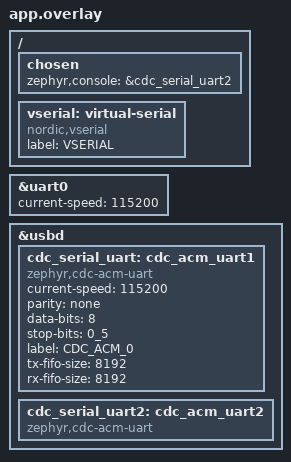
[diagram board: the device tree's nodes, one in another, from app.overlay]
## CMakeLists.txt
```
#
# Copyright (c) 2022 Nordic Semiconductor ASA
#
# SPDX-License-Identifier: LicenseRef-Nordic-5-Clause
#

cmake_minimum_required(VERSION 3.20.5)
cmake_policy(SET CMP0057 NEW)

find_package(Zephyr REQUIRED HINTS $ENV{ZEPHYR_BASE})

add_compile_options(-Wno-unused-function -Wno-unused-variable)


list(APPEND CMAKE_MODULE_PATH ${ZEPHYR_BASE}/modules/nanopb)
include(nanopb)

project(embedded80211_serial)

target_include_directories(app PUBLIC ${ZEPHYR_BASE}/subsys/net/ip)

set(PROTO_DIR ${CMAKE_CURRENT_SOURCE_DIR}/../protos)
set(PROTO_FILES ${PROTO_DIR}/wifi.proto ${PROTO_DIR}/network_interface.proto)

# Generate C sources from .proto files
# The function will create targets for generating the .pb.c and .pb.h files.
zephyr_nanopb_sources(app ${PROTO_FILES})

# we need to be able to include generated protobuf header files
zephyr_library_include_directories(${CMAKE_CURRENT_BINARY_DIR})

target_include_directories(app PUBLIC src)

#src/wifi_data.c


target_sources(app PRIVATE
	src/main.c
	src/multiplexer.c
)

if(CONFIG_SERIAL_PROXY_WIFI_MGMT)
	target_sources(app PRIVATE src/wifi_mgmt_proxy.c)
endif()

if(CONFIG_SERIAL_PROXY_WIFI_DATA)
	target_sources(app PRIVATE src/wifi_data.c)
endif()

if(CONFIG_SERIAL_PROXY_NET_IF_MGMT)
	target_sources(app PRIVATE src/net_if_mgmt_proxy.c)
endif()

if(CONFIG_SERIAL_PROXY_BT)
	target_sources(app PRIVATE src/bt_proxy.c)
endif()

if(CONFIG_SERIAL_PROXY_OT)
	target_sources(app PRIVATE src/ot_proxy.c)
endif()

if(CONFIG_SERIAL_PROXY_VSERIAL)
	target_sources(app PRIVATE src/vserial.c)
endif()

add_subdirectory(src/serial)
```

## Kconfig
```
#
# Copyright (c) 2022 Nordic Semiconductor
#
# SPDX-License-Identifier: LicenseRef-Nordic-5-Clause
#

source "Kconfig.zephyr"

menu "Nordic Sta sample"

config CONNECTION_IDLE_TIMEOUT
	int "Time to be waited for a station to connect"
	default 30

config NRF70_QSPI_ENCRYPTION_KEY
	string "16 bytes QSPI encryption key, only for testing purposes"
	depends on BOARD_NRF7002DK_NRF5340_CPUAPP
	help
	  Specify the QSPI encryption key

config STA_CONN_TIMEOUT_SEC
	int "Overall Connection timeout i.e., time to be waited for a station to connect and get an IP address"
	# Zephyr DHCP retry is 1 minute, so set the default to 70 seconds
	default 70
	# 512 has no special meaning, just a reasonable upper limit
	range 0 512
	help
	  Specify the connection timeout, in seconds. This is the overall timeout i.e., time to be waited for
	  a station to connect and get an IP address. DHCP retries should be taken into account when setting
	  this value. If the timeout is set to 0, the connection will not timeout.

config STA_SAMPLE_START_WIFI_THREAD_STACK_SIZE
	int "Stack size for Wi-Fi start thread"
	default 4096
	help
	  Set the stack size for the Wi-Fi start thread.

# Wi-Fi management bearer configuration
choice WIFI_MGMT_BEARER
	bool "Enable Wi-Fi management bearer"
	default WIFI_MGMT_BEARER_SERIAL_USB
	help
	  Enable the Wi-Fi management bearer. This allows the sample to use the Wi-Fi management interface
	  for operations such as scanning and connecting to networks.

config WIFI_MGMT_BEARER_SERIAL_UART
	bool "Enable Wi-Fi management bearer over UART"
	help
	  Enable the Wi-Fi management bearer over UART. This allows the sample to communicate with the Wi-Fi
	  management interface using a serial connection.

config WIFI_MGMT_BEARER_SERIAL_USB
	bool "Enable Wi-Fi management bearer over USB"
	help
	  Enable the Wi-Fi management bearer over USB. This allows the sample to communicate with the Wi-Fi
	  management interface using a USB connection.
endchoice

# Host/device role configuration
choice SERIAL_ROLE
	bool "Serial role selection"
	default SERIAL_DEVICE_ROLE
	help
	  Select whether this node operates as an RCP device (responds to host
	  commands over serial) or as a Zephyr host-driver (issues commands to a
	  remote device over serial).

config SERIAL_DEVICE_ROLE
	bool "RCP device role"
	help
	  This node acts as a Radio Co-Processor device. It receives management
	  and data frames from a host over the serial link and calls the
	  corresponding Zephyr Wi-Fi / net_if / BT APIs.

config SERIAL_HOST_ROLE
	bool "Zephyr host-driver role"
	help
	  This node acts as the serial host driver. It sends management and data
	  frames to a remote RCP device and exposes the results to the local
	  Zephyr networking stack.
endchoice

# Virtual serial over protocol configuration
config VSERIAL_ENABLE
	bool "Enable virtual serial device over common link protocol"
	default y
	help
	  Enable a virtual serial device that operates over the common link protocol.
	  This exposes serial port semantics over the protocol, with support for
	  baud rate, stop bits, and parity shadowing for readback compatibility.

if VSERIAL_ENABLE

config VSERIAL_RX_BUF_SIZE
	int "Virtual serial RX buffer size"
	default 256
	range 64 4096
	help
	  Size of the receive ring buffer for virtual serial data.

config VSERIAL_TX_BUF_SIZE
	int "Virtual serial TX buffer size"
	default 256
	range 64 4096
	help
	  Size of the transmit buffer for virtual serial data.

endif # VSERIAL_ENABLE

menu "Serial multiplexer"

config SERIAL_PROTOCOL_MULTIPLEXER
	bool "Enable serial protocol multiplexer"
	default y
	help
	  Enable a technology multiplexer that maps protocol traffic types to
	  selected serial interfaces. This allows routing one or many technology
	  proxies over the same interface.

if SERIAL_PROTOCOL_MULTIPLEXER

config SERIAL_MUX_IFACE_UART
	bool "Enable UART interface in multiplexer"
	default y if SERIAL
	depends on SERIAL
	help
	  Register the UART transport as a selectable interface target for
	  technology proxy egress.

config SERIAL_MUX_IFACE_USB
	bool "Enable USB CDC ACM interface in multiplexer"
	default y if USBD_CDC_ACM_CLASS
	depends on USBD_CDC_ACM_CLASS
	help
	  Register the USB CDC ACM transport as a selectable interface target for
	  technology proxy egress. Requires the USB device stack next CDC ACM
	  class (USBD_CDC_ACM_CLASS) and a "zephyr,cdc-acm-uart" devicetree node.

config WIFI_MGMT_PROXY_MAX_SCAN_RESULTS
	int "Maximum Wi-Fi scan results reported to the host"
	default 32
	range 1 32
	depends on SERIAL_PROXY_WIFI_MGMT
	help
	  Upper bound for the scan results collected and reported to the host in
	  a single ScanDoneEvent notification. The limit is also capped by the
	  protobuf schema (ScanDoneEvent.all_results max_count).

config SERIAL_PROXY_WIFI_MGMT
	bool "Enable Wi-Fi management proxy"
	default y

config SERIAL_PROXY_WIFI_DATA
	bool "Enable Wi-Fi data proxy"
	default y

config SERIAL_PROXY_NET_IF_MGMT
	bool "Enable net_if management proxy"
	default y

config SERIAL_PROXY_BT
	bool "Enable Bluetooth HCI proxy"
	default y
	depends on BT
	help
	  Enable the Bluetooth HCI proxy. Host HCI packets (traffic type HCI)
	  are bridged to the local Bluetooth controller through the Zephyr
	  raw HCI channel (CONFIG_BT_HCI_RAW); controller events are reported
	  back to the host as HCI traffic frames.

config SERIAL_PROXY_OT
	bool "Enable OpenThread/Spinel proxy"
	default y

config SERIAL_PROXY_VSERIAL
	bool "Enable virtual serial proxy"
	default y if VSERIAL_ENABLE
	depends on VSERIAL_ENABLE

choice SERIAL_MUX_WIFI_MGMT_IFACE
	bool "Wi-Fi management egress interface"
	depends on SERIAL_PROXY_WIFI_MGMT
	default SERIAL_MUX_WIFI_MGMT_IFACE_USB if SERIAL_MUX_IFACE_USB
	default SERIAL_MUX_WIFI_MGMT_IFACE_UART if SERIAL_MUX_IFACE_UART

config SERIAL_MUX_WIFI_MGMT_IFACE_UART
	bool "UART"
	depends on SERIAL_MUX_IFACE_UART

config SERIAL_MUX_WIFI_MGMT_IFACE_USB
	bool "USB CDC ACM"
	depends on SERIAL_MUX_IFACE_USB

endchoice

choice SERIAL_MUX_WIFI_DATA_IFACE
	bool "Wi-Fi data egress interface"
	depends on SERIAL_PROXY_WIFI_DATA
	default SERIAL_MUX_WIFI_DATA_IFACE_USB if SERIAL_MUX_IFACE_USB
	default SERIAL_MUX_WIFI_DATA_IFACE_UART if SERIAL_MUX_IFACE_UART

config SERIAL_MUX_WIFI_DATA_IFACE_UART
	bool "UART"
	depends on SERIAL_MUX_IFACE_UART

config SERIAL_MUX_WIFI_DATA_IFACE_USB
	bool "USB CDC ACM"
	depends on SERIAL_MUX_IFACE_USB

endchoice

choice SERIAL_MUX_NET_IF_MGMT_IFACE
	bool "net_if management egress interface"
	depends on SERIAL_PROXY_NET_IF_MGMT
	default SERIAL_MUX_NET_IF_MGMT_IFACE_USB if SERIAL_MUX_IFACE_USB
	default SERIAL_MUX_NET_IF_MGMT_IFACE_UART if SERIAL_MUX_IFACE_UART

config SERIAL_MUX_NET_IF_MGMT_IFACE_UART
	bool "UART"
	depends on SERIAL_MUX_IFACE_UART

config SERIAL_MUX_NET_IF_MGMT_IFACE_USB
	bool "USB CDC ACM"
	depends on SERIAL_MUX_IFACE_USB

endchoice

choice SERIAL_MUX_BT_IFACE
	bool "Bluetooth HCI egress interface"
	depends on SERIAL_PROXY_BT
	default SERIAL_MUX_BT_IFACE_USB if SERIAL_MUX_IFACE_USB
	default SERIAL_MUX_BT_IFACE_UART if SERIAL_MUX_IFACE_UART

config SERIAL_MUX_BT_IFACE_UART
	bool "UART"
	depends on SERIAL_MUX_IFACE_UART

config SERIAL_MUX_BT_IFACE_USB
	bool "USB CDC ACM"
	depends on SERIAL_MUX_IFACE_USB

endchoice

choice SERIAL_MUX_OT_IFACE
	bool "OpenThread egress interface"
	depends on SERIAL_PROXY_OT
	default SERIAL_MUX_OT_IFACE_USB if SERIAL_MUX_IFACE_USB
	default SERIAL_MUX_OT_IFACE_UART if SERIAL_MUX_IFACE_UART

config SERIAL_MUX_OT_IFACE_UART
	bool "UART"
	depends on SERIAL_MUX_IFACE_UART

config SERIAL_MUX_OT_IFACE_USB
	bool "USB CDC ACM"
	depends on SERIAL_MUX_IFACE_USB

endchoice

choice SERIAL_MUX_VSERIAL_IFACE
	bool "Virtual serial egress interface"
	depends on SERIAL_PROXY_VSERIAL
	default SERIAL_MUX_VSERIAL_IFACE_USB if SERIAL_MUX_IFACE_USB
	default SERIAL_MUX_VSERIAL_IFACE_UART if SERIAL_MUX_IFACE_UART

config SERIAL_MUX_VSERIAL_IFACE_UART
	bool "UART"
	depends on SERIAL_MUX_IFACE_UART

config SERIAL_MUX_VSERIAL_IFACE_USB
	bool "USB CDC ACM"
	depends on SERIAL_MUX_IFACE_USB

endchoice

endif # SERIAL_PROTOCOL_MULTIPLEXER

endmenu

endmenu

rsource "src/serial/Kconfig"
```

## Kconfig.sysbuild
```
#
# Sysbuild configuration for the embedded80211_serial application.
#
# The Bluetooth controller (nRF5340 SoftDevice Controller) runs on the
# network core. The netcore image is the Nordic "ipc_radio" application,
# which serializes the controller's HCI over the IPC service to this
# application core (zephyr,bt-hci = &bt_hci_ipc0 in the board devicetree).

#### Netcore image
config NRF_DEFAULT_IPC_RADIO
	default y

# Enable Bluetooth serialization to the network core via HCI IPC.
config NETCORE_IPC_RADIO_BT_HCI_IPC
	default y

source "share/sysbuild/Kconfig"
```

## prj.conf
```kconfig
#
# Copyright (c) 2025 Mikko Jaakkola
#
#
CONFIG_WIFI=y
CONFIG_WIFI_NRF70=y

# WPA supplicant
CONFIG_WIFI_NM_WPA_SUPPLICANT=y
CONFIG_WIFI_READY_LIB=y
CONFIG_NRF_WIFI_RPU_RECOVERY=y
# Low power must be disabled for monitor-mode raw RX capture: with LPM the
# nRF7002 RPU puts the radio to sleep after ~10 ms idle, and in monitor mode
# there is no beacon/DTIM to wake it, so air frames are never captured.
# (Reference: nrf/tests/drivers/nrf_wifi/raw_tx_rx/prj.conf.)
# Note: this also disables CONFIG_NRF_WIFI_RPU_RECOVERY (depends on LPM).
CONFIG_NRF_WIFI_LOW_POWER=n
# Fixed MAC address (OTP read may fail on this board)
CONFIG_WIFI_FIXED_MAC_ADDRESS_ENABLED=y
CONFIG_WIFI_FIXED_MAC_ADDRESS="02:00:00:00:00:01"

CONFIG_WIFI_CREDENTIALS=y
CONFIG_WIFI_CREDENTIALS_STATIC=y
CONFIG_WIFI_CREDENTIALS_STATIC_SSID="Myssid"
CONFIG_WIFI_CREDENTIALS_STATIC_PASSWORD="Mypassword"

# Networking
CONFIG_NETWORKING=y
CONFIG_NET_SOCKETS=y
CONFIG_NET_LOG=y
CONFIG_NET_IPV4=n
CONFIG_NET_UDP=n
CONFIG_NET_TCP=n
CONFIG_NET_DHCPV4=n

# Raw 802.11 frame injection + capture (data connectivity testing):
# - TX: an AF_PACKET socket carries a raw_tx header + 802.11 frame; the driver
#   recognizes the magic number and transmits the frame without TCP/IP.
# - RX: with the packet filter set to WIFI_PACKET_FILTER_ALL the driver
#   delivers captured air frames (including one it just transmitted) back on an
#   AF_PACKET socket, so a transmitted test frame can be verified over serial.
CONFIG_NRF70_RAW_DATA_TX=y
CONFIG_NRF70_RAW_DATA_RX=y
CONFIG_NRF70_PROMISC_DATA_RX=y

# Required for net_capture_pkt() to deliver sniffer frames to AF_PACKET
# sockets. Without this, the monitor-mode RX path is a no-op.
CONFIG_NET_CAPTURE=y

CONFIG_NET_PKT_RX_COUNT=60
CONFIG_NET_PKT_TX_COUNT=16
CONFIG_NRF70_RX_NUM_BUFS=16

# Below section is the primary contributor to SRAM and is currently
# tuned for performance, but this will be revisited in the future.
CONFIG_NET_BUF_RX_COUNT=60
CONFIG_NET_BUF_TX_COUNT=32
CONFIG_HEAP_MEM_POOL_SIZE=37000
CONFIG_HEAP_MEM_POOL_IGNORE_MIN=y
CONFIG_NRF_WIFI_CTRL_HEAP_SIZE=20000
CONFIG_NRF_WIFI_DATA_HEAP_SIZE=100000
CONFIG_NET_TC_TX_COUNT=1

#CONFIG_NET_IF_UNICAST_IPV4_ADDR_COUNT=1
CONFIG_NET_MAX_CONTEXTS=5
CONFIG_NET_CONTEXT_SYNC_RECV=y

CONFIG_INIT_STACKS=y

CONFIG_NET_L2_ETHERNET=y
CONFIG_NET_L2_ETHERNET_MGMT=y

CONFIG_NET_CONFIG_SETTINGS=y
CONFIG_NET_CONFIG_INIT_TIMEOUT=0

CONFIG_NET_SOCKETS_POLL_MAX=10

# Memories
CONFIG_MAIN_STACK_SIZE=5200
CONFIG_NET_TX_STACK_SIZE=4096
CONFIG_NET_RX_STACK_SIZE=4096
CONFIG_STA_SAMPLE_START_WIFI_THREAD_STACK_SIZE=5200

# Debugging
CONFIG_STACK_SENTINEL=y
CONFIG_DEBUG_COREDUMP=y
CONFIG_DEBUG_COREDUMP_BACKEND_LOGGING=y
CONFIG_DEBUG_COREDUMP_MEMORY_DUMP_MIN=y
CONFIG_SHELL_CMDS_RESIZE=n


# Kernel options
CONFIG_ENTROPY_GENERATOR=y

# Logging
CONFIG_LOG=y
CONFIG_LOG_BUFFER_SIZE=2048

#CONFIG_NET_CONFIG_MY_IPV4_ADDR="192.168.1.99"
#CONFIG_NET_CONFIG_MY_IPV4_NETMASK="255.255.255.0"
#CONFIG_NET_CONFIG_MY_IPV4_GW="192.168.1.1"

# printing of scan results puts pressure on queues in new locking
# design in net_mgmt. So, use a higher timeout for a crowded
# environment.
CONFIG_NET_MGMT_EVENT_QUEUE_TIMEOUT=5000

# Nanopb
CONFIG_NANOPB=y

# Bluetooth LE
# The controller is the nRF5340 on-chip SoftDevice Controller running on the
# network core (the ipc_radio netcore image, see Kconfig.sysbuild). The
# application core exposes a raw HCI channel to the host over the common
# link protocol (traffic type HCI, see src/bt_proxy.c).
CONFIG_BT=y
CONFIG_BT_HCI_RAW=y
CONFIG_MBOX=y
CONFIG_IPC_SERVICE=y

# Enable USB Subsystem (new USB device stack)
CONFIG_USB_DEVICE_STACK_NEXT=y

# Enable CDC ACM class for USB device stack next
CONFIG_USBD_CDC_ACM_CLASS=y

# Initialize and enable CDC ACM serial backend at boot
CONFIG_CDC_ACM_SERIAL_INITIALIZE_AT_BOOT=y
CONFIG_CDC_ACM_SERIAL_ENABLE_AT_BOOT=y
# Single instance mode registers "cdc_acm_0" = first zephyr,cdc-acm-uart node
# (cdc_serial_uart, the multiplexer's USB backend bound by serial_usb.c).
# MULTIPLE_INSTANCES=y would instead only expose the chosen console/shell/mcumgr
# UARTs (zephyr,console = cdc_serial_uart2), leaving the multiplexer port
# unregistered and invisible to the host.
CONFIG_CDC_ACM_SERIAL_MULTIPLE_INSTANCES=n

# Temporary USB VID/PID for testing
CONFIG_CDC_ACM_SERIAL_VID=0x2FE3
CONFIG_CDC_ACM_SERIAL_PID=0x0001
CONFIG_CDC_ACM_SERIAL_PRODUCT_STRING="My Zephyr CDC-ACM Device"
CONFIG_CDC_ACM_SERIAL_MANUFACTURER_STRING="Test Vendor"

# Serial
CONFIG_SERIAL=y
 # Needed for USB CDC ACM. Aysynchronous serial port
# API would be better for all other serial ports.
CONFIG_UART_INTERRUPT_DRIVEN=y

# Enable RTT (Real-Time Transfer)
CONFIG_RTT_CONSOLE=y

# Choose SEGGER RTT as the backend (most common)
CONFIG_USE_SEGGER_RTT=y
CONFIG_SEGGER_RTT_BUFFER_SIZE_UP=131072
CONFIG_SEGGER_RTT_BUFFER_SIZE_DOWN=64
# Re-init the RTT control block unconditionally on every boot. The CB lives in
# a persistent section (not zeroed by startup), so the default strong-check
# mode reuses offsets left by the previous boot: the ring stays full of stale
# data and the skip-mode log writer drops everything new. Fresh ring per boot.
CONFIG_SEGGER_RTT_INIT_MODE_ALWAYS=y

CONFIG_UART_CONSOLE=y

# Workqueue
CONFIG_SYSTEM_WORKQUEUE_STACK_SIZE=2048
CONFIG_SYSTEM_WORKQUEUE_PRIORITY=-1

# Enable events
CONFIG_EVENTS=y
```

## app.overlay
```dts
&uart0 {
    status = "okay";
    current-speed = <115200>; // Set baud rate
};


zephyr_udc0: &usbd {
    status = "okay";
    cdc_serial_uart: cdc_acm_uart1 { // This creates an instance named "CDC_ACM_0"
        compatible = "zephyr,cdc-acm-uart";
		current-speed = <115200>;
		parity = "none";
		data-bits = <8>;
		stop-bits = "0_5";
        label = "CDC_ACM_0";
        /* Must hold a full protocol frame (4 B header + 4096 B payload =
         * 4100 B; next power of two is 8192). The CDC ACM driver's
         * poll_out silently discards bytes when this ring is full, so any
         * smaller value truncates large frames (e.g. SCAN_DONE
         * notifications) whenever the host drains the USB endpoint slower
         * than the ring fills.
         */
        tx-fifo-size = <8192>;
        rx-fifo-size = <8192>;
        status = "okay";
    };
    cdc_serial_uart2: cdc_acm_uart2 { // This creates an instance named "CDC_ACM_1"
        compatible = "zephyr,cdc-acm-uart";
    };
};

/ {
     chosen {
         zephyr,console = &cdc_serial_uart2;
     };

     vserial: virtual-serial {
         compatible = "nordic,vserial";
         status = "okay";
         label = "VSERIAL";
     };
};
```

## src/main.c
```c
/*
 * Copyright (c) 2022 Nordic Semiconductor ASA
 *
 * SPDX-License-Identifier: LicenseRef-Nordic-5-Clause
 */

/** @file
 * @brief WiFi station sample
 */

#include <zephyr/logging/log.h>
LOG_MODULE_REGISTER(embedded80211_serial, CONFIG_LOG_DEFAULT_LEVEL);

#include <zephyr/kernel.h>
#include <stdio.h>
#include <stdlib.h>
#include <zephyr/shell/shell.h>
#include <zephyr/sys/printk.h>
#include <zephyr/init.h>

#include <zephyr/net/net_if.h>
#include <zephyr/net/wifi_mgmt.h>
#include <zephyr/net/net_event.h>
#include <zephyr/drivers/gpio.h>

#ifdef CONFIG_WIFI_READY_LIB
#include <net/wifi_ready.h>
#endif /* CONFIG_WIFI_READY_LIB */

#if defined(CONFIG_BOARD_NRF7002DK_NRF7001_NRF5340_CPUAPP) || \
	defined(CONFIG_BOARD_NRF7002DK_NRF5340_CPUAPP)
#include <zephyr/drivers/wifi/nrf_wifi/bus/qspi_if.h>
#endif

#include "net_private.h"

#define WIFI_SHELL_MODULE "wifi"

#define WIFI_SHELL_MGMT_EVENTS (NET_EVENT_WIFI_CONNECT_RESULT |		\
				NET_EVENT_WIFI_DISCONNECT_RESULT)

#define MAX_SSID_LEN        32
#define STATUS_POLLING_MS   300

/* 1000 msec = 1 sec */
#define LED_SLEEP_TIME_MS   100

/* The devicetree node identifier for the "led0" alias. */
#define LED0_NODE DT_ALIAS(led0)
/*
 * A build error on this line means your board is unsupported.
 * See the sample documentation for information on how to fix this.
 */
static const struct gpio_dt_spec led = GPIO_DT_SPEC_GET(LED0_NODE, gpios);

static struct net_mgmt_event_callback wifi_shell_mgmt_cb;
static struct net_mgmt_event_callback net_shell_mgmt_cb;

#ifdef CONFIG_WIFI_READY_LIB
static K_SEM_DEFINE(wifi_ready_state_changed_sem, 0, 1);
static bool wifi_ready_status;
#endif /* CONFIG_WIFI_READY_LIB */

static struct {
	const struct shell *sh;
	union {
		struct {
			uint8_t connected	: 1;
			uint8_t connect_result	: 1;
			uint8_t disconnect_requested	: 1;
			uint8_t _unused		: 5;
		};
		uint8_t all;
	};
} context;

void toggle_led(void)
{
	int ret;

	if (!device_is_ready(led.port)) {
		LOG_ERR("LED device is not ready");
		return;
	}

	ret = gpio_pin_configure_dt(&led, GPIO_OUTPUT_ACTIVE);
	if (ret < 0) {
		LOG_ERR("Error %d: failed to configure LED pin", ret);
		return;
	}

	while (1) {
		if (context.connected) {
			gpio_pin_toggle_dt(&led);
			k_msleep(LED_SLEEP_TIME_MS);
		} else {
			gpio_pin_set_dt(&led, 0);
			k_msleep(LED_SLEEP_TIME_MS);
		}
	}
}

K_THREAD_DEFINE(led_thread_id, 1024, toggle_led, NULL, NULL, NULL,
		7, 0, 0);

static int cmd_wifi_status(void)
{
	struct net_if *iface = net_if_get_default();
	struct wifi_iface_status status = { 0 };

	if (net_mgmt(NET_REQUEST_WIFI_IFACE_STATUS, iface, &status,
				sizeof(struct wifi_iface_status))) {
		LOG_ERR("Status request failed");

		return -ENOEXEC;
	}

	/* The caller polls every STATUS_POLLING_MS; log only state changes so
	 * the log backend is not flooded with identical lines. */
	static bool have_last;
	static int last_state;

	if (have_last && status.state == last_state) {
		return 0;
	}
	have_last = true;
	last_state = status.state;

	LOG_INF("==================");
	LOG_INF("State: %s", wifi_state_txt(status.state));

	if (status.state >= WIFI_STATE_ASSOCIATED) {
		uint8_t mac_string_buf[sizeof("xx:xx:xx:xx:xx:xx")];

		LOG_INF("Interface Mode: %s",
		       wifi_mode_txt(status.iface_mode));
		LOG_INF("Link Mode: %s",
		       wifi_link_mode_txt(status.link_mode));
		LOG_INF("SSID: %.32s", status.ssid);
		LOG_INF("BSSID: %s",
		       net_sprint_ll_addr_buf(
				status.bssid, WIFI_MAC_ADDR_LEN,
				mac_string_buf, sizeof(mac_string_buf)));
		LOG_INF("Band: %s", wifi_band_txt(status.band));
		LOG_INF("Channel: %d", status.channel);
		LOG_INF("Security: %s", wifi_security_txt(status.security));
		LOG_INF("MFP: %s", wifi_mfp_txt(status.mfp));
		LOG_INF("RSSI: %d", status.rssi);
	}
	return 0;
}

static void handle_wifi_connect_result(struct net_mgmt_event_callback *cb)
{
	const struct wifi_status *status =
		(const struct wifi_status *) cb->info;

	if (context.connected) {
		return;
	}

	if (status->status) {
		LOG_ERR("Connection failed (%d)", status->status);
	} else {
		LOG_INF("Connected");
		context.connected = true;
	}

	context.connect_result = true;
}

static void handle_wifi_disconnect_result(struct net_mgmt_event_callback *cb)
{
	const struct wifi_status *status =
		(const struct wifi_status *) cb->info;

	if (!context.connected) {
		return;
	}

	if (context.disconnect_requested) {
		LOG_INF("Disconnection request %s (%d)",
			 status->status ? "failed" : "done",
					status->status);
		context.disconnect_requested = false;
	} else {
		LOG_INF("Received Disconnected");
		context.connected = false;
	}

	cmd_wifi_status();
}

static void wifi_mgmt_event_handler(struct net_mgmt_event_callback *cb,
				     uint64_t mgmt_event, struct net_if *iface)
{
	switch (mgmt_event) {
	case NET_EVENT_WIFI_CONNECT_RESULT:
		handle_wifi_connect_result(cb);
		break;
	case NET_EVENT_WIFI_DISCONNECT_RESULT:
		handle_wifi_disconnect_result(cb);
		break;
	default:
		break;
	}
}

static void net_mgmt_event_handler(struct net_mgmt_event_callback *cb,
				    uint64_t mgmt_event, struct net_if *iface)
{
	switch (mgmt_event) {
	case NET_EVENT_IPV4_DHCP_BOUND:
		//print_dhcp_ip(cb);
		break;
	default:
		break;
	}
}

int bytes_from_str(const char *str, uint8_t *bytes, size_t bytes_len)
{
	size_t i;
	char byte_str[3];

	if (strlen(str) != bytes_len * 2) {
		LOG_ERR("Invalid string length: %zu (expected: %d)\n",
			strlen(str), bytes_len * 2);
		return -EINVAL;
	}

	for (i = 0; i < bytes_len; i++) {
		memcpy(byte_str, str + i * 2, 2);
		byte_str[2] = '\0';
		bytes[i] = strtol(byte_str, NULL, 16);
	}

	return 0;
}

int start_app(void)
{
#if defined(CONFIG_BOARD_NRF7002DK_NRF7001_NRF5340_CPUAPP) || \
	defined(CONFIG_BOARD_NRF7002DK_NRF5340_CPUAPP)
	if (strlen(CONFIG_NRF70_QSPI_ENCRYPTION_KEY)) {
		int ret;
		char key[QSPI_KEY_LEN_BYTES];

		ret = bytes_from_str(CONFIG_NRF70_QSPI_ENCRYPTION_KEY, key, sizeof(key));
		if (ret) {
			LOG_ERR("Failed to parse encryption key: %d\n", ret);
			return 0;
		}

		LOG_DBG("QSPI Encryption key: ");
		for (int i = 0; i < QSPI_KEY_LEN_BYTES; i++) {
			LOG_DBG("%02x", key[i]);
		}
		LOG_DBG("\n");

		ret = qspi_enable_encryption(key);
		if (ret) {
			LOG_ERR("Failed to enable encryption: %d\n", ret);
			return 0;
		}
		LOG_INF("QSPI Encryption enabled");
	} else {
		LOG_INF("QSPI Encryption disabled");
	}
#endif /* CONFIG_BOARD_NRF700XDK_NRF5340 */

	while (1) {
#ifdef CONFIG_WIFI_READY_LIB
		int ret;

		LOG_INF("Waiting for Wi-Fi to be ready");
		ret = k_sem_take(&wifi_ready_state_changed_sem, K_FOREVER);
		if (ret) {
			LOG_ERR("Failed to take semaphore: %d", ret);
			return ret;
		}

		if (!wifi_ready_status) {
			LOG_INF("Wi-Fi is not ready");
			/* Perform any cleanup and stop using Wi-Fi and wait for
			 * Wi-Fi to be ready
			 */
			continue;
		}
#endif /* CONFIG_WIFI_READY_LIB */
		/* Proxy mode: the host drives Wi-Fi over the serial link
		 * (scan / connect / AP via cli_test). Do not auto-connect
		 * here — a boot-time connect would race the host's
		 * requests and can leave the driver stuck in SCANNING. */
		LOG_INF("Wi-Fi ready — proxy mode (host-driven over serial)");
		k_sleep(K_FOREVER);
	}

	return 0;
}

#ifdef CONFIG_WIFI_READY_LIB
void start_wifi_thread(void);
#define THREAD_PRIORITY K_PRIO_COOP(CONFIG_NUM_COOP_PRIORITIES - 1)
K_THREAD_DEFINE(start_wifi_thread_id, CONFIG_STA_SAMPLE_START_WIFI_THREAD_STACK_SIZE,
		start_wifi_thread, NULL, NULL, NULL,
		THREAD_PRIORITY, 0, -1);

void start_wifi_thread(void)
{
	start_app();
}

void wifi_ready_cb(bool wifi_ready)
{
	LOG_DBG("Is Wi-Fi ready?: %s", wifi_ready ? "yes" : "no");
	wifi_ready_status = wifi_ready;
	k_sem_give(&wifi_ready_state_changed_sem);
}
#endif /* CONFIG_WIFI_READY_LIB */

void net_mgmt_callback_init(void)
{
	memset(&context, 0, sizeof(context));

	net_mgmt_init_event_callback(&wifi_shell_mgmt_cb,
				     wifi_mgmt_event_handler,
				     WIFI_SHELL_MGMT_EVENTS);

	net_mgmt_add_event_callback(&wifi_shell_mgmt_cb);

	net_mgmt_init_event_callback(&net_shell_mgmt_cb,
				     net_mgmt_event_handler,
				     NET_EVENT_IPV4_DHCP_BOUND);

	net_mgmt_add_event_callback(&net_shell_mgmt_cb);

	LOG_INF("Starting %s with CPU frequency: %d MHz", CONFIG_BOARD, SystemCoreClock/MHZ(1));
	k_sleep(K_SECONDS(1));
}

#ifdef CONFIG_WIFI_READY_LIB
static int register_wifi_ready(void)
{
	int ret = 0;
	wifi_ready_callback_t cb;
	struct net_if *iface = net_if_get_first_wifi();

	if (!iface) {
		LOG_ERR("Failed to get Wi-Fi interface");
		return -1;
	}

	cb.wifi_ready_cb = wifi_ready_cb;

	LOG_DBG("Registering Wi-Fi ready callbacks");
	ret = register_wifi_ready_callback(cb, iface);
	if (ret) {
		LOG_ERR("Failed to register Wi-Fi ready callbacks %s", strerror(ret));
		return ret;
	}

	return ret;
}
#endif /* CONFIG_WIFI_READY_LIB */

int main(void)
{
	int ret = 0;

	int counter = 12;

	while(counter--) {
		LOG_INF("Starting %s with CPU frequency: %d MHz", CONFIG_BOARD, SystemCoreClock/MHZ(1));
		k_sleep(K_SECONDS(1));
	}

	net_mgmt_callback_init();

#ifdef CONFIG_WIFI_READY_LIB
	ret = register_wifi_ready();
	if (ret) {
		return ret;
	}
	k_thread_start(start_wifi_thread_id);
#else
	start_app();
#endif /* CONFIG_WIFI_READY_LIB */
	return ret;
}
```

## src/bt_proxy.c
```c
/*
 * bt_proxy.c - Bluetooth HCI proxy (raw HCI bridge)
 *
 * Bridges the common link protocol's HCI traffic type (3) to the Zephyr
 * raw HCI channel (CONFIG_BT_HCI_RAW):
 *
 *  host -> device: link frames (type HCI) carrying raw H:4 HCI packets
 *  (command / ACL data) are validated and injected into the controller
 *  with bt_send().
 *
 *  device -> host: packets received from the controller (events, ACL
 *  data) are queued by the raw HCI channel into an internal fifo, drained
 *  by a dedicated thread and reported to the host as link frames (type
 *  HCI) through the serial multiplexer.
 *
 * The controller is the nRF5340 on-chip SoftDevice Controller running on
 * the network core; the application core reaches it over IPC
 * (zephyr,bt-hci chosen = bt_hci_ipc0). The host is the Bluetooth host:
 * it drives the controller with HCI commands (e.g. HCI_Reset) and
 * receives controller events.
 */
#include <zephyr/kernel.h>
#include <zephyr/logging/log.h>
#include <zephyr/sys/byteorder.h>

#include <zephyr/bluetooth/buf.h>
#include <zephyr/bluetooth/hci_raw.h>
#include <zephyr/bluetooth/hci_types.h>

#include "multiplexer.h"
#include "serial/serial.h"

LOG_MODULE_REGISTER(bt_proxy, LOG_LEVEL_INF);

/* H:4 packet types (subset of the Zephyr HCI H4 definitions). */
#define BT_HCI_H4_CMD 0x01 /* HCI Command packet */
#define BT_HCI_H4_ACL 0x02 /* HCI ACL Data packet */
#define BT_HCI_H4_SCO 0x03 /* HCI Synchronous Data packet */
#define BT_HCI_H4_EVT 0x04 /* HCI Event packet */
#define BT_HCI_H4_ISO 0x05 /* HCI ISO Data packet */

/*
 * Accumulation buffer for incoming HCI frames from the serial link.
 * Sized for the largest H:4 packet the host may send (255 B ACL + 1 B
 * H:4 type); larger link payloads are rejected with OUT_OF_BUFFERS.
 */
#define BT_PROXY_BUFFER_SIZE 512U

static uint8_t hci_rx_buffer[BT_PROXY_BUFFER_SIZE];
static size_t hci_rx_buffer_len = 0;

/*
 * Raw HCI channel receive fifo: the controller's packets (delivered via
 * the IPC HCI driver) are queued here as net_bufs, each prefixed with
 * its H:4 type byte (see bt_buf_get_rx() in the BT subsystem).
 */
K_FIFO_DEFINE(hci_raw_rx_fifo);

/*
 * Controller -> host: drain the raw channel fifo and forward each HCI
 * packet to the host as an HCI traffic frame.
 *
 * Runs in a dedicated thread because serial egress applies backpressure
 * (bounded wait for TX space); blocking the system workqueue here would
 * stall the serial RX parser and every other work item.
 */
static void hci_event_tx_thread(void *fifo, void *arg1, void *arg2)
{
	ARG_UNUSED(arg1);
	ARG_UNUSED(arg2);

	struct k_fifo *queue = (struct k_fifo *)fifo;

	while (true) {
		struct net_buf *buf = k_fifo_get(queue, K_FOREVER);

		if (buf == NULL) {
			continue;
		}

		LOG_DBG("Controller -> host: H4=0x%02x len=%u",
			buf->data[0], buf->len);

		int err = serial_mux_send(SERIAL_TYPE_HCI, buf->data, buf->len);

		if (err != 0) {
			LOG_WRN("Failed to forward HCI event to host (%d)", err);
		}

		net_buf_unref(buf);
	}
}

K_THREAD_STACK_DEFINE(hci_event_tx_stack, 2048);
static struct k_thread hci_event_tx_thread_data;

/**
 * @brief Acquire buffer space for incoming HCI frame from serial protocol.
 *
 * The serial layer calls this to get a buffer for incoming data.
 * A static buffer is used; the serial layer writes the frame payload in
 * chunks and reports each chunk with bt_proxy_commit_data().
 */
bool bt_proxy_acquire_buffer(uint8_t **data, size_t len)
{
	if ((hci_rx_buffer_len + len) > BT_PROXY_BUFFER_SIZE) {
		LOG_WRN("Requested %zu bytes exceeds buffer capacity (current: %zu)",
			len, hci_rx_buffer_len);
		return false;
	}

	*data = &hci_rx_buffer[hci_rx_buffer_len];
	return true;
}

/**
 * @brief Commit data chunk - called as serial data arrives.
 *
 * May be called multiple times as chunks of the HCI frame arrive.
 */
void bt_proxy_commit_data(size_t len)
{
	hci_rx_buffer_len += len;
	LOG_DBG("Accumulated %zu bytes (total: %zu)", len, hci_rx_buffer_len);
}

/**
 * @brief Validate the accumulated H:4 packet.
 *
 * @return 0 if the packet is well formed, -EINVAL otherwise.
 */
static int hci_packet_validate(uint8_t h4_type, size_t len)
{
	switch (h4_type) {
	case BT_HCI_H4_CMD: {
		/* opcode (2) + param_len (1) + params */
		size_t param_len = hci_rx_buffer[3];

		return (len == 4U + param_len) ? 0 : -EINVAL;
	}
	case BT_HCI_H4_ACL: {
		/* addr (2) + len (2) + pb/flags (1) + payload */
		uint16_t payload_len = sys_le16_to_cpu(*(const uint16_t *)&hci_rx_buffer[3]);

		return (len == 6U + payload_len) ? 0 : -EINVAL;
	}
	default:
		return -ENOTSUP;
	}
}

/**
 * @brief Complete HCI message received - send to the Bluetooth controller.
 *
 * Called by the serial layer when a complete HCI frame (raw H:4 packet)
 * is available. The packet is validated, mapped to a raw HCI TX buffer
 * and handed to the controller.
 */
void bt_proxy_message_complete(size_t len)
{
	if (len < 2U || len > BT_PROXY_BUFFER_SIZE) {
		LOG_ERR("Invalid HCI frame length %zu", len);
		hci_rx_buffer_len = 0;
		return;
	}

	uint8_t h4_type = hci_rx_buffer[0];

	LOG_DBG("Received HCI frame: H4=0x%02x len=%zu", h4_type, len);

	int err = hci_packet_validate(h4_type, len);
	if (err != 0) {
		LOG_WRN("Malformed HCI packet (H4=0x%02x len=%zu): %d",
			h4_type, len, err);
		hci_rx_buffer_len = 0;
		return;
	}

	enum bt_buf_type buf_type;

	switch (h4_type) {
	case BT_HCI_H4_CMD:
		buf_type = BT_BUF_CMD;
		break;
	case BT_HCI_H4_ACL:
		buf_type = BT_BUF_ACL_OUT;
		break;
	default:
		/* Unreachable: validated above. */
		hci_rx_buffer_len = 0;
		return;
	}

	/* bt_buf_get_tx() prepends the H:4 type byte; pass the payload
	 * after it.
	 */
	struct net_buf *buf =
		bt_buf_get_tx(buf_type, K_NO_WAIT, &hci_rx_buffer[1], len - 1);

	if (buf == NULL) {
		LOG_ERR("No HCI TX buffer available (H4=0x%02x)", h4_type);
		hci_rx_buffer_len = 0;
		return;
	}

	err = bt_send(buf);
	if (err != 0) {
		LOG_ERR("Failed to send HCI packet to controller: %d", err);
		net_buf_unref(buf);
	} else {
		LOG_DBG("HCI packet sent to controller (H4=0x%02x len=%zu)",
			h4_type, len);
	}

	/* Reset buffer for the next frame. */
	hci_rx_buffer_len = 0;
}

static int bt_proxy_init(void)
{
	int err = bt_enable_raw(&hci_raw_rx_fifo);

	if (err != 0) {
		LOG_ERR("bt_enable_raw failed: %d", err);
		return err;
	}

	k_thread_create(&hci_event_tx_thread_data, hci_event_tx_stack,
		K_THREAD_STACK_SIZEOF(hci_event_tx_stack),
		hci_event_tx_thread, (void *)&hci_raw_rx_fifo, NULL, NULL,
		7, 0, K_NO_WAIT);
	k_thread_start(&hci_event_tx_thread_data);

	LOG_INF("BT HCI proxy ready (raw HCI channel over IPC)");
	return 0;
}

SYS_INIT(bt_proxy_init, APPLICATION, CONFIG_APPLICATION_INIT_PRIORITY);
```

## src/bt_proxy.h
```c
#ifndef _BT_PROXY_H_
#define _BT_PROXY_H_

#include <zephyr/device.h>

/**
 * @brief Acquire buffer space for incoming HCI frame data.
 *
 * Called by the serial protocol layer when it needs to store incoming HCI data.
 * The proxy provides a buffer where the data will be written.
 *
 * @param data Output: pointer to allocated buffer
 * @param len Number of bytes to allocate
 * @return true if buffer allocated successfully, false otherwise
 */
bool bt_proxy_acquire_buffer(uint8_t **data, size_t len);

/**
 * @brief Commit data - called when a chunk of HCI frame data is written.
 *
 * May be called multiple times as data arrives in chunks.
 *
 * @param len Number of bytes committed to the buffer
 */
void bt_proxy_commit_data(size_t len);

/**
 * @brief Complete HCI message received - send to Bluetooth stack.
 *
 * Called by the serial protocol layer when a complete HCI frame is available.
 * The proxy forwards this to the Zephyr Bluetooth controller.
 *
 * @param len Total length of the complete HCI frame
 */
void bt_proxy_message_complete(size_t len);

/**
 * @brief Initialize the Bluetooth proxy.
 *
 * Sets up the HCI device reference and initializes the proxy.
 *
 * @return 0 on success, negative error code on failure
 */
int bt_proxy_init(void);

#endif /* _BT_PROXY_H_ */
```

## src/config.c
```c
#include "serial/serial.h"
#include "wifi_mgmt_proxy.h"
#include "wifi_data.h"
#include "net_if_mgmt_proxy.h"
#include "vserial.h"

/* Forward declarations for BT/OT stub files (no separate headers) */
bool bt_proxy_acquire_buffer(uint8_t **data, size_t len);
void bt_proxy_commit_data(size_t len);
void bt_proxy_message_complete(size_t len);

bool ot_proxy_acquire_buffer(uint8_t **data, size_t len);
void ot_proxy_commit_data(size_t len);
void ot_proxy_message_complete(size_t len);

struct client_callbacks client_cb[SERIAL_TYPE_UNKNOWN] = {
    [SERIAL_TYPE_WIFI_MGMT] = {
        .acquire_buffer  = wifi_mgmt_acquire_buffer,
        .commit_data     = wifi_mgmt_commit_data,
        .message_complete = wifi_mgmt_message_complete,
    },
    [SERIAL_TYPE_WIFI_DATA] = {
        .acquire_buffer  = wifi_data_acquire_buffer,
        .commit_data     = wifi_data_commit_data,
        .message_complete = wifi_data_message_complete,
    },
    [SERIAL_TYPE_NET_IF_MGMT] = {
        .acquire_buffer  = net_if_mgmt_acquire_buffer,
        .commit_data     = net_if_mgmt_commit_data,
        .message_complete = net_if_mgmt_message_complete,
    },
    [SERIAL_TYPE_HCI] = {
        .acquire_buffer  = bt_proxy_acquire_buffer,
        .commit_data     = bt_proxy_commit_data,
        .message_complete = bt_proxy_message_complete,
    },
    [SERIAL_TYPE_THREAD] = {
        .acquire_buffer  = ot_proxy_acquire_buffer,
        .commit_data     = ot_proxy_commit_data,
        .message_complete = ot_proxy_message_complete,
    },
    [SERIAL_TYPE_NET_OFFLOADING] = {
        /* Reserved — not implemented */
        .acquire_buffer  = NULL,
        .commit_data     = NULL,
        .message_complete = NULL,
    },
    [SERIAL_TYPE_AT_CMD] = {
        /* Reserved — not implemented */
        .acquire_buffer  = NULL,
        .commit_data     = NULL,
        .message_complete = NULL,
    },
    [SERIAL_TYPE_PROTOCOL_INFO] = {
        /* Handled inline in serial layer — no client callbacks needed */
        .acquire_buffer  = NULL,
        .commit_data     = NULL,
        .message_complete = NULL,
    },
    [SERIAL_TYPE_VSERIAL] = {
        .acquire_buffer  = vserial_acquire_buffer,
        .commit_data     = vserial_commit_data,
        .message_complete = vserial_message_complete,
    },
};
```

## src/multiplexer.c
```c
#include <zephyr/logging/log.h>
#include <errno.h>

#include "multiplexer.h"
#include "wifi_mgmt_proxy.h"
#include "wifi_data.h"
#include "net_if_mgmt_proxy.h"
#include "vserial.h"

/* Forward declarations for BT/OT files without separate headers. */
bool bt_proxy_acquire_buffer(uint8_t **data, size_t len);
void bt_proxy_commit_data(size_t len);
void bt_proxy_message_complete(size_t len);

bool ot_proxy_acquire_buffer(uint8_t **data, size_t len);
void ot_proxy_commit_data(size_t len);
void ot_proxy_message_complete(size_t len);

LOG_MODULE_REGISTER(serial_mux, LOG_LEVEL_INF);

struct mux_iface_entry {
    bool registered;
    const struct device *dev;
    struct serial_config *config;
};

static struct mux_iface_entry mux_ifaces[SERIAL_MUX_IFACE_COUNT];

static struct client_callbacks mux_callbacks[SERIAL_TYPE_UNKNOWN] = {
#if defined(CONFIG_SERIAL_PROXY_WIFI_MGMT)
    [SERIAL_TYPE_WIFI_MGMT] = {
        .acquire_buffer = wifi_mgmt_acquire_buffer,
        .commit_data = wifi_mgmt_commit_data,
        .message_complete = wifi_mgmt_message_complete,
    },
#endif
#if defined(CONFIG_SERIAL_PROXY_WIFI_DATA)
    [SERIAL_TYPE_WIFI_DATA] = {
        .acquire_buffer = wifi_data_acquire_buffer,
        .commit_data = wifi_data_commit_data,
        .message_complete = wifi_data_message_complete,
    },
#endif
#if defined(CONFIG_SERIAL_PROXY_NET_IF_MGMT)
    [SERIAL_TYPE_NET_IF_MGMT] = {
        .acquire_buffer = net_if_mgmt_acquire_buffer,
        .commit_data = net_if_mgmt_commit_data,
        .message_complete = net_if_mgmt_message_complete,
    },
#endif
#if defined(CONFIG_SERIAL_PROXY_BT)
    [SERIAL_TYPE_HCI] = {
        .acquire_buffer = bt_proxy_acquire_buffer,
        .commit_data = bt_proxy_commit_data,
        .message_complete = bt_proxy_message_complete,
    },
#endif
#if defined(CONFIG_SERIAL_PROXY_OT)
    [SERIAL_TYPE_THREAD] = {
        .acquire_buffer = ot_proxy_acquire_buffer,
        .commit_data = ot_proxy_commit_data,
        .message_complete = ot_proxy_message_complete,
    },
#endif
#if defined(CONFIG_SERIAL_PROXY_VSERIAL)
    [SERIAL_TYPE_VSERIAL] = {
        .acquire_buffer = vserial_acquire_buffer,
        .commit_data = vserial_commit_data,
        .message_complete = vserial_message_complete,
    },
#endif
};

static bool serial_mux_iface_enabled(enum serial_mux_iface_id iface_id)
{
    switch (iface_id) {
    case SERIAL_MUX_IFACE_UART:
#if defined(CONFIG_SERIAL_MUX_IFACE_UART)
        return true;
#else
        return false;
#endif
    case SERIAL_MUX_IFACE_USB:
#if defined(CONFIG_SERIAL_MUX_IFACE_USB)
        return true;
#else
        return false;
#endif
    default:
        return false;
    }
}

static enum serial_mux_iface_id serial_mux_route_for_type(enum SerialType type)
{
    switch (type) {
    case SERIAL_TYPE_WIFI_MGMT:
#if defined(CONFIG_SERIAL_MUX_WIFI_MGMT_IFACE_USB)
        return SERIAL_MUX_IFACE_USB;
#else
        return SERIAL_MUX_IFACE_UART;
#endif
    case SERIAL_TYPE_WIFI_DATA:
#if defined(CONFIG_SERIAL_MUX_WIFI_DATA_IFACE_USB)
        return SERIAL_MUX_IFACE_USB;
#else
        return SERIAL_MUX_IFACE_UART;
#endif
    case SERIAL_TYPE_NET_IF_MGMT:
#if defined(CONFIG_SERIAL_MUX_NET_IF_MGMT_IFACE_USB)
        return SERIAL_MUX_IFACE_USB;
#else
        return SERIAL_MUX_IFACE_UART;
#endif
    case SERIAL_TYPE_HCI:
#if defined(CONFIG_SERIAL_MUX_BT_IFACE_USB)
        return SERIAL_MUX_IFACE_USB;
#else
        return SERIAL_MUX_IFACE_UART;
#endif
    case SERIAL_TYPE_THREAD:
#if defined(CONFIG_SERIAL_MUX_OT_IFACE_USB)
        return SERIAL_MUX_IFACE_USB;
#else
        return SERIAL_MUX_IFACE_UART;
#endif
    case SERIAL_TYPE_VSERIAL:
#if defined(CONFIG_SERIAL_MUX_VSERIAL_IFACE_USB)
        return SERIAL_MUX_IFACE_USB;
#else
        return SERIAL_MUX_IFACE_UART;
#endif
    default:
        return SERIAL_MUX_IFACE_UART;
    }
}

int serial_mux_register_interface(enum serial_mux_iface_id iface_id,
                                  const struct device *dev,
                                  struct serial_config *config)
{
    if (iface_id >= SERIAL_MUX_IFACE_COUNT || dev == NULL || config == NULL) {
        return -EINVAL;
    }

    if (!serial_mux_iface_enabled(iface_id)) {
        LOG_WRN("Interface %d registration ignored: disabled by Kconfig", iface_id);
        return -ENOTSUP;
    }

    mux_ifaces[iface_id].registered = true;
    mux_ifaces[iface_id].dev = dev;
    mux_ifaces[iface_id].config = config;

    LOG_INF("Registered serial interface %d (%s)", iface_id, dev->name);
    return 0;
}

const struct client_callbacks *serial_mux_get_callbacks(enum SerialType type)
{
    if (type >= SERIAL_TYPE_UNKNOWN) {
        return NULL;
    }

    if (mux_callbacks[type].acquire_buffer == NULL ||
        mux_callbacks[type].commit_data == NULL ||
        mux_callbacks[type].message_complete == NULL) {
        return NULL;
    }

    return &mux_callbacks[type];
}

uint16_t serial_mux_supported_types_mask(void)
{
    uint16_t mask = 0;

    for (int i = 0; i < SERIAL_TYPE_UNKNOWN; i++) {
        if (serial_mux_get_callbacks((enum SerialType)i) != NULL) {
            mask |= (uint16_t)(1U << i);
        }
    }

    mask |= (uint16_t)(1U << SERIAL_TYPE_PROTOCOL_INFO);
    return mask;
}

int serial_mux_send(enum SerialType type, const uint8_t *payload, size_t len)
{
    enum serial_mux_iface_id iface_id = serial_mux_route_for_type(type);

    if (iface_id >= SERIAL_MUX_IFACE_COUNT || !mux_ifaces[iface_id].registered ||
        mux_ifaces[iface_id].config == NULL) {
        LOG_ERR("No serial interface registered for type %d (iface %d)", type, iface_id);
        return -ENODEV;
    }

    return serial_send_frame(mux_ifaces[iface_id].config,
                             type,
                             ERROR_TYPE_NO_ERROR,
                             false,
                             payload,
                             len);
}
```

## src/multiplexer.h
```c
#ifndef _MULTIPLEXER_H_
#define _MULTIPLEXER_H_

#include <zephyr/device.h>
#include <stdint.h>

#include "serial/serial.h"

enum serial_mux_iface_id {
    SERIAL_MUX_IFACE_UART = 0,
    SERIAL_MUX_IFACE_USB,
    SERIAL_MUX_IFACE_COUNT,
};

int serial_mux_register_interface(enum serial_mux_iface_id iface_id,
                                  const struct device *dev,
                                  struct serial_config *config);

const struct client_callbacks *serial_mux_get_callbacks(enum SerialType type);

uint16_t serial_mux_supported_types_mask(void);

int serial_mux_send(enum SerialType type, const uint8_t *payload, size_t len);

#endif /* _MULTIPLEXER_H_ */
```

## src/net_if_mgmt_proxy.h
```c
#ifndef _NET_IF_MGMT_PROXY_H_
#define _NET_IF_MGMT_PROXY_H_

#include <serial/serial.h>

bool net_if_mgmt_acquire_buffer(uint8_t **data, size_t len);
void net_if_mgmt_commit_data(size_t len);
void net_if_mgmt_message_complete(size_t len);

#endif /* _NET_IF_MGMT_PROXY_H_ */
```

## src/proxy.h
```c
#ifndef _PROXY_H_
#define _PROXY_H_




#endif // _PROXY_H_
```

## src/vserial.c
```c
#include <zephyr/kernel.h>
#include <zephyr/logging/log.h>
#include <zephyr/drivers/uart.h>
#include <zephyr/sys/ring_buffer.h>
#include <string.h>

#include "vserial.h"

LOG_MODULE_REGISTER(vserial, LOG_LEVEL_DBG);

/*
 * Virtual serial interface over the common link protocol.
 *
 * Per AGENTS.md:
 *   - Serial-port semantics are exposed over the common protocol (VSERIAL traffic type).
 *   - Baud rate, stop bits, and parity are shadowed for readback compatibility.
 *   - Values do not affect transport behavior.
 *
 * Registered as a standard Zephyr UART/serial driver exposing read/write operations
 * through the serial subsystem.
 */

#define VSERIAL_RX_BUF_SIZE CONFIG_VSERIAL_RX_BUF_SIZE
#define VSERIAL_TX_BUF_SIZE CONFIG_VSERIAL_TX_BUF_SIZE

struct vserial_data {
    /* Configuration state (shadowed) */
    uint32_t baud_rate;
    uint8_t  stop_bits;
    uint8_t  parity;

    /* RX ring buffer for data coming from protocol stack */
    uint8_t rx_buf[VSERIAL_RX_BUF_SIZE];
    struct ring_buf rx_ring;

    /* TX buffer for data going to protocol stack */
    uint8_t tx_buf[VSERIAL_TX_BUF_SIZE];

    /* Callback for interrupt-driven operation */
    uart_irq_callback_user_data_t callback;
    void *callback_user_data;

    /* Mutex for thread-safe access */
    struct k_mutex lock;
};

static struct vserial_data vserial_inst = {
    .baud_rate = 115200,
    .stop_bits = 1,
    .parity    = 0,
};

/**
 * @brief Poll for input character (from protocol stack to application)
 * @return 0 if char available in *c, -1 if no data
 */
static int vserial_poll_in(const struct device *dev, unsigned char *c)
{
    struct vserial_data *data = dev->data;
    size_t read_len = 0;

    k_mutex_lock(&data->lock, K_FOREVER);
    read_len = ring_buf_get(&data->rx_ring, c, 1);
    k_mutex_unlock(&data->lock);

    return (read_len > 0) ? 0 : -1;
}

/**
 * @brief Transmit a character (from application to protocol stack)
 *
 * For efficiency, this buffers characters. A full implementation would batch them
 * into VSERIAL protocol frames.
 */
static void vserial_poll_out(const struct device *dev, unsigned char c)
{
    LOG_DBG("vserial: TX char 0x%02x", c);
}

/**
 * @brief Minimal UART driver API - polling only
 */
static const struct uart_driver_api vserial_driver_api = {
    .poll_in  = vserial_poll_in,
    .poll_out = vserial_poll_out,
};

/**
 * @brief Initialize virtual serial device
 */
static int vserial_init(const struct device *dev)
{
    struct vserial_data *data = dev->data;

    k_mutex_init(&data->lock);
    ring_buf_init(&data->rx_ring, VSERIAL_RX_BUF_SIZE, data->rx_buf);

    LOG_INF("vserial: initialized (RX=%u, TX=%u)", VSERIAL_RX_BUF_SIZE, VSERIAL_TX_BUF_SIZE);
    return 0;
}

/**
 * @brief Device tree definition for vserial
 */
DEVICE_DT_DEFINE(DT_NODELABEL(vserial),
                 vserial_init,
                 NULL,
                 &vserial_inst,
                 NULL,
                 POST_KERNEL,
                 CONFIG_SERIAL_INIT_PRIORITY,
                 &vserial_driver_api);

/* ============================================================================
 * Public API for protocol stack
 * ============================================================================ */

bool vserial_acquire_buffer(uint8_t **data, size_t len)
{
    if (len > VSERIAL_TX_BUF_SIZE) {
        LOG_WRN("vserial: TX frame too large (%zu), dropping", len);
        return false;
    }
    *data = vserial_inst.tx_buf;
    return true;
}

void vserial_commit_data(size_t len)
{
    /* Buffer already filled, no action needed */
}

void vserial_message_complete(size_t len)
{
    /*
     * A message has been received from the protocol stack with virtual serial data.
     * Add it to the RX ring buffer so applications can read it.
     */
    if (len > VSERIAL_RX_BUF_SIZE) {
        LOG_WRN("vserial: RX message too large (%zu), dropping", len);
        return;
    }

    k_mutex_lock(&vserial_inst.lock, K_FOREVER);

    uint32_t written = ring_buf_put(&vserial_inst.rx_ring, vserial_inst.tx_buf, len);
    if (written < len) {
        LOG_WRN("vserial: RX ring buffer overflow (wanted %zu, wrote %u)", len, written);
    }

    /* Trigger callback if registered */
    if (vserial_inst.callback) {
        const struct device *dev = DEVICE_DT_GET(DT_NODELABEL(vserial));
        if (dev != NULL && device_is_ready(dev)) {
            vserial_inst.callback(dev, vserial_inst.callback_user_data);
        }
    }

    k_mutex_unlock(&vserial_inst.lock);

    LOG_DBG("vserial: received %u bytes from protocol stack", written);
}
```

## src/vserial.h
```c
#ifndef _VSERIAL_H_
#define _VSERIAL_H_

#include <zephyr/device.h>
#include <zephyr/drivers/uart.h>
#include <stdint.h>
#include <stddef.h>
#include <stdbool.h>

/*
 * Virtual serial interface over the common link protocol.
 *
 * Per AGENTS.md:
 *   - Serial-port semantics are exposed over the common protocol (VSERIAL traffic type).
 *   - Baud rate, stop bits, and parity are shadowed for readback compatibility.
 *   - Values do not affect transport behavior.
 *
 * Registered as a standard Zephyr UART/serial driver exposing read/write operations
 * through the serial subsystem.
 */

/**
 * @brief Acquire buffer for outgoing virtual serial data
 * @param data Pointer to receive buffer address
 * @param len Requested length
 * @return true if buffer acquired, false if too large or unavailable
 */
bool vserial_acquire_buffer(uint8_t **data, size_t len);

/**
 * @brief Mark data committed to buffer (does nothing, data is already in buffer)
 * @param len Length of data
 */
void vserial_commit_data(size_t len);

/**
 * @brief Process complete incoming virtual serial message
 * @param len Length of message payload
 */
void vserial_message_complete(size_t len);

#endif /* _VSERIAL_H_ */
```
